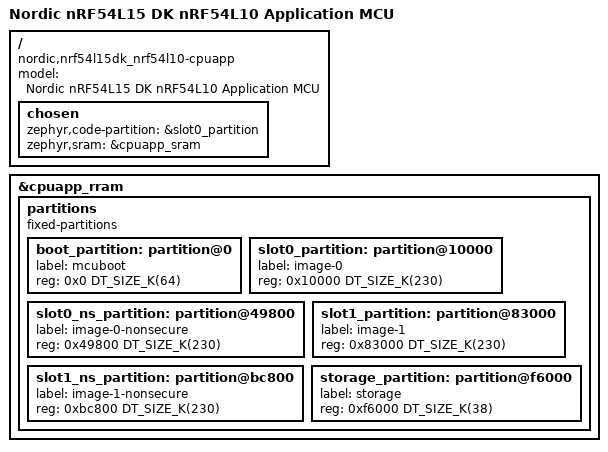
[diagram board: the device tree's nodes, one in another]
/*
 * Copyright (c) 2024 Nordic Semiconductor ASA
 *
 * SPDX-License-Identifier: Apache-2.0
 */

/dts-v1/;

#include <nordic/nrf54l10_cpuapp.dtsi>
#include "nrf54l_05_10_15_cpuapp_common.dtsi"

/ {
	compatible = "nordic,nrf54l15dk_nrf54l10-cpuapp";
	model = "Nordic nRF54L15 DK nRF54L10 Application MCU";

	chosen {
		zephyr,code-partition = &slot0_partition;
		zephyr,sram = &cpuapp_sram;
	};
};

&cpuapp_rram {
	partitions {
		compatible = "fixed-partitions";
		#address-cells = <1>;
		#size-cells = <1>;
		boot_partition: partition@0 {
			label = "mcuboot";
			reg = <0x0 DT_SIZE_K(64)>;
		};
		slot0_partition: partition@10000 {
			label = "image-0";
			reg = <0x10000 DT_SIZE_K(230)>;
		};
		slot0_ns_partition: partition@49800 {
			label = "image-0-nonsecure";
			reg = <0x49800 DT_SIZE_K(230)>;
		};
		slot1_partition: partition@83000 {
			label = "image-1";
			reg = <0x83000 DT_SIZE_K(230)>;
		};
		slot1_ns_partition: partition@bc800 {
			label = "image-1-nonsecure";
			reg = <0xbc800 DT_SIZE_K(230)>;
		};
		storage_partition: partition@f6000 {
			label = "storage";
			reg = <0xf6000 DT_SIZE_K(38)>;
		};
	};
};
